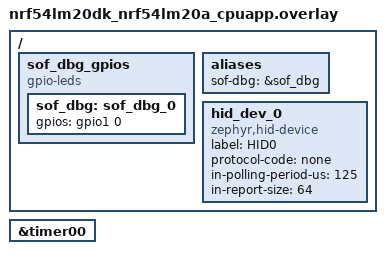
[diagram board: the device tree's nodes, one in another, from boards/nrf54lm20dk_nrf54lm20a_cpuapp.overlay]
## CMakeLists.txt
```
#
# Copyright (c) 2018 Nordic Semiconductor
#
# SPDX-License-Identifier: LicenseRef-Nordic-5-Clause
#
cmake_minimum_required(VERSION 3.20.0)

find_package(Zephyr REQUIRED HINTS $ENV{ZEPHYR_BASE})
project(NONE)

include(${ZEPHYR_BASE}/samples/subsys/usb/common/common.cmake)

FILE(GLOB app_sources src/*.c)
# NORDIC SDK APP START
target_sources(app PRIVATE ${app_sources})
# NORDIC SDK APP END

# if (CONFIG_CODE_DATA_RELOCATION)
# zephyr_code_relocate(FILES src/main.c LOCATION MYTCM NOKEEP)
# zephyr_code_relocate(FILES ../../../subsys/esb/esb.c LOCATION MYTCM NOKEEP)
# zephyr_code_relocate(FILES ../../../subsys/esb/esb_dppi.c LOCATION MYTCM NOKEEP)
# endif()
```

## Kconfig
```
#
# Copyright (c) 2020 Nordic Semiconductor
#
# SPDX-License-Identifier: LicenseRef-Nordic-5-Clause
#

source "Kconfig.zephyr"
source "samples/subsys/usb/common/Kconfig.sample_usbd"
```

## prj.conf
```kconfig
#
# Copyright (c) 2019 Nordic Semiconductor ASA
#
# SPDX-License-Identifier: LicenseRef-Nordic-5-Clause
#
CONFIG_NCS_SAMPLES_DEFAULTS=y

CONFIG_SPIN_VALIDATE=n
CONFIG_PM=n
CONFIG_TIMESLICING=n

CONFIG_DK_LIBRARY=y

CONFIG_USB_DEVICE_STACK_NEXT=y
CONFIG_UDC_DRIVER_LOG_LEVEL_WRN=y

CONFIG_USBD_HID_SUPPORT=y
CONFIG_USBD_LOG_LEVEL_WRN=y
CONFIG_USBD_HID_LOG_LEVEL_WRN=y

CONFIG_SAMPLE_USBD_MANUFACTURER="Nordic Semiconductor"
CONFIG_SAMPLE_USBD_PRODUCT="ESB dongle demo"
CONFIG_SAMPLE_USBD_SELF_POWERED=n
CONFIG_SAMPLE_USBD_MAX_POWER=50

CONFIG_NRFX_GPPI=y

CONFIG_NRFX_TIMER=y
CONFIG_LOG=y
```

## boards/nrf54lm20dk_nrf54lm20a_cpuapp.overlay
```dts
/*
 * Copyright (c) 2025 Nordic Semiconductor
 *
 * SPDX-License-Identifier: LicenseRef-Nordic-5-Clause
 */

/ {
	/* SOF debug GPIO: toggle on each timer IRQ (20us after SOF).
	 * Connect logic analyzer probe here to verify SOF->timer chain.
	 * Change <&gpio1 0 ...> to any free header pin as needed.
	 */
	sof_dbg_gpios {
		compatible = "gpio-leds";
		sof_dbg: sof_dbg_0 {
			gpios = <&gpio1 0 GPIO_ACTIVE_HIGH>;
		};
	};

	aliases {
		sof-dbg = &sof_dbg;
	};

	hid_dev_0: hid_dev_0 {
		compatible = "zephyr,hid-device";
		label = "HID0";
		protocol-code = "none";
		in-polling-period-us = <125>;
		in-report-size = <64>;
	};
};

&timer00 {
	status = "okay";
};
```

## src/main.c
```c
/*
 * Copyright (c) 2018 Nordic Semiconductor ASA
 *
 * SPDX-License-Identifier: LicenseRef-Nordic-5-Clause
 */
#include <string.h>
#include <zephyr/device.h>
#include <zephyr/devicetree.h>
#include <zephyr/usb/usbd.h>
#include <zephyr/logging/log.h>
#include <nrfx.h>
#include <zephyr/kernel.h>
#include <zephyr/types.h>
#include <zephyr/pm/device_runtime.h>
#include <dk_buttons_and_leds.h>
#include "app_usbd.h"

LOG_MODULE_REGISTER(usb_sof_dppi, LOG_LEVEL_INF);

static void usbd_in_report_done_cb(void)
{
	LOG_INF("USB device in report done callback");

}

int main(void)
{
	int err;

	LOG_INF("Enhanced ShockBurst prx sample");

	err = app_usbd_init(usbd_in_report_done_cb);
	if (err) {
		LOG_ERR("Failed to initialize USB device, err %d", err);
		return 0;
	}
	err = app_usbd_enable();
	if (err) {
		LOG_ERR("Failed to enable USB device, err %d", err);
		return 0;
	}

	/* return to idle thread */
	return 0;
}
```

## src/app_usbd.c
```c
/*
 * Copyright (c) 2025 Nordic Semiconductor
 *
 * SPDX-License-Identifier: LicenseRef-Nordic-5-Clause
 */

#include <zephyr/usb/usb_device.h>
#include <zephyr/usb/usbd.h>
#include <zephyr/usb/class/usbd_hid.h>
#include <sample_usbd.h>
#include "app_usbd.h"
#include <hal/nrf_gpiote.h>
#include <helpers/nrfx_gppi.h>
#include <nrfx_timer.h>
#include <zephyr/drivers/gpio.h>
#include <zephyr/logging/log.h>
LOG_MODULE_REGISTER(app_usbd, LOG_LEVEL_INF);

/** @brief Symbol specifying time in milliseconds to wait for handler execution. */
#define TIME_TO_WAIT_MS 5000UL
#define TIME_TO_WAIT_US 20UL
/* NRFX_TIMER */
/** @brief Symbol specifying timer instance to be used in nrfx_timer/timer example. */
#define TIMER_INST_IDX 00

/** @brief TIMER instance used in the example. */
static nrfx_timer_t timer_inst = NRFX_TIMER_INSTANCE(NRF_TIMER_INST_GET(TIMER_INST_IDX));

/* Debug GPIO: toggles each time the timer fires (20us after USB SOF). */
static const struct gpio_dt_spec sof_dbg_gpio = GPIO_DT_SPEC_GET(DT_ALIAS(sof_dbg), gpios);


static int get_report_cb(const struct device *dev,
			 const uint8_t type, const uint8_t id, const uint16_t len,
			 uint8_t *const buf);
static void input_report_done_cb(const struct device *dev, const uint8_t *const report);
static void output_report_cb(const struct device *dev,
			     const uint16_t len,
			     const uint8_t *const buf);


static const uint8_t hid_report_desc[] = HID_MOUSE_REPORT_DESC(2);

static app_usbd_in_report_done_cb usr_in_report_done_cb;


/**
 * @brief Function for handling TIMER driver events.
 *
 * @param[in] event_type Timer event.
 * @param[in] p_context  General purpose parameter set during initialization of
 *                       the timer. This parameter can be used to pass
 *                       additional information to the handler function, for
 *                       example, the timer ID.
 */
static void timer_handler(nrf_timer_event_t event_type, void * p_context)
{
    if(event_type == NRF_TIMER_EVENT_COMPARE0)
    {
        gpio_pin_toggle_dt(&sof_dbg_gpio);
        // char * p_msg = p_context;
        // LOG_INF("Timer finished. Context passed to the handler: >%s<", p_msg);
    }
}

static int set_report_cb(const struct device *dev,
			 const uint8_t type, const uint8_t id, const uint16_t len,
			 const uint8_t *const buf)
{
	if (type != HID_REPORT_TYPE_OUTPUT) {
		return -ENOTSUP;
	}

	return 0;
}

static void iface_ready_cb(const struct device *dev, const bool ready)
{
}

static uint32_t idle_duration;

static void set_idle_cb(const struct device *dev,
			const uint8_t id, const uint32_t duration)
{
	idle_duration = duration;
}

static uint32_t get_idle_cb(const struct device *dev, const uint8_t id)
{
	return idle_duration;
}

static uint32_t idle_duration;

static const struct hid_device_ops hid_ops = {
	.iface_ready = iface_ready_cb,
	.get_report = get_report_cb,
	.set_report = set_report_cb,
	.input_report_done = input_report_done_cb,
	.output_report = output_report_cb,
	.set_idle = set_idle_cb,
	.get_idle = get_idle_cb
};

static struct usbd_context *sample_usbd;

static const struct device *hid_device = DEVICE_DT_GET_ONE(zephyr_hid_device);


static void output_report_cb(const struct device *dev,
			     const uint16_t len,
			     const uint8_t *const buf)
{
}

static void msg_cb(struct usbd_context *const usbd_ctx,
		   const struct usbd_msg *const msg)
{
	if (usbd_can_detect_vbus(usbd_ctx)) {
		if (msg->type == USBD_MSG_VBUS_READY) {
			usbd_enable(usbd_ctx);
		} else if (msg->type == USBD_MSG_VBUS_REMOVED) {
			usbd_disable(usbd_ctx);
		}
	}
}

int app_usbd_init(app_usbd_in_report_done_cb cb)
{
	int err;

	err = hid_device_register(hid_device,
				  hid_report_desc,
				  sizeof(hid_report_desc),
				  &hid_ops);

	if (!err) {
		sample_usbd = sample_usbd_init_device(msg_cb);
		err = (sample_usbd) ? 0 : -ENODEV;
	}

	if (!err) {
		usr_in_report_done_cb = cb;
	}

	return err;
}

int timer_init(void)
{
    int status;
    (void)status;

#if defined(__ZEPHYR__)
    IRQ_CONNECT(NRFX_IRQ_NUMBER_GET(NRF_TIMER_INST_GET(TIMER_INST_IDX)), IRQ_PRIO_LOWEST,
                nrfx_timer_irq_handler, &timer_inst, 0);
#endif
    uint32_t base_frequency = NRF_TIMER_BASE_FREQUENCY_GET(timer_inst.p_reg);
    nrfx_timer_config_t config = NRFX_TIMER_DEFAULT_CONFIG(base_frequency);
    config.bit_width = NRF_TIMER_BIT_WIDTH_32;
    config.p_context = "Some context";
    status = nrfx_timer_init(&timer_inst, &config, timer_handler);
    NRFX_ASSERT(status == 0);
    nrfx_timer_clear(&timer_inst);

    /* Configure SOF debug GPIO as output, initially low. */
    gpio_pin_configure_dt(&sof_dbg_gpio, GPIO_OUTPUT_LOW);
    /* Creating variable desired_ticks to store the output of nrfx_timer_ms_to_ticks function */
    // uint32_t desired_ticks = nrfx_timer_ms_to_ticks(&timer_inst, TIME_TO_WAIT_MS);
    // LOG_INF("Time to wait: %lu ms", TIME_TO_WAIT_MS);	
	uint32_t desired_ticks = nrfx_timer_us_to_ticks(&timer_inst, TIME_TO_WAIT_US);
    LOG_INF("Time to wait: %lu us", TIME_TO_WAIT_US);	
    /*
     * Setting the timer channel NRF_TIMER_CC_CHANNEL0 in the extended compare mode to stop the timer and
     * trigger an interrupt if internal counter register is equal to desired_ticks.
     */
    nrfx_timer_extended_compare(&timer_inst, NRF_TIMER_CC_CHANNEL0, desired_ticks,
                                NRF_TIMER_SHORT_COMPARE0_CLEAR_MASK | NRF_TIMER_SHORT_COMPARE0_STOP_MASK, true);

    // nrfx_timer_enable(&timer_inst);	
    // LOG_INF("Timer status: %s", nrfx_timer_is_enabled(&timer_inst) ? "enabled" : "disabled");
	return 0;
}

int dppi_usb_sof_timer_gpiote_setup(void)
{
	uint32_t usbhs_start_task = (uint32_t)&NRF_USBHS->TASKS_START;
	uint32_t usbhs_domain_id = nrfx_gppi_domain_id_get(usbhs_start_task);

	/* --- Connection 1: USBHS SOF → Timer START --- */
	uint32_t timer_task_addr = nrf_timer_task_address_get(timer_inst.p_reg, NRF_TIMER_TASK_START);
	uint32_t timer_domain_id = nrfx_gppi_domain_id_get(timer_task_addr);

	int err;
	nrfx_gppi_handle_t gppi_handle_timer;

	err = nrfx_gppi_domain_conn_alloc(usbhs_domain_id, timer_domain_id, &gppi_handle_timer);
	if (err) {
		LOG_ERR("Timer conn alloc failed: %d", err);
	}

	/* Retrieve the allocated DPPI channel in the USBHS domain and configure PUBLISH_SOF. */
	uint32_t usbhs_dppi_ch = nrfx_gppi_domain_channel_get(gppi_handle_timer, usbhs_domain_id);
	NRF_USBHS->PUBLISH_SOF = (usbhs_dppi_ch << USBHS_PUBLISH_SOF_CHIDX_Pos) |
							 (USBHS_PUBLISH_SOF_EN_Enabled << USBHS_PUBLISH_SOF_EN_Pos);

	err = nrfx_gppi_ep_attach(timer_task_addr, gppi_handle_timer);
	if (err) {
		LOG_ERR("Timer ep attach failed: %d", err);
	}

	/* --- Connection 2: USBHS SOF → GPIOTE30 OUT (reuse the same source DPPI channel) --- */
	uint32_t gpiote_task_addr = nrf_gpiote_task_address_get(NRF_GPIOTE30, NRF_GPIOTE_TASK_OUT_0);
	uint32_t gpiote_domain_id = nrfx_gppi_domain_id_get(gpiote_task_addr);

	nrfx_gppi_handle_t gppi_handle_gpiote;

	/*
	 * Pass the already-allocated USBHS DPPI channel as p_resource so that
	 * nrfx_gppi_ext_conn_alloc reuses it instead of allocating a new one.
	 * Both PPIB bridges will then be driven by the same PUBLISH_SOF channel,
	 * triggering both tasks simultaneously on every SOF event.
	 */
	nrfx_gppi_resource_t usbhs_resource = {
		.domain_id = (uint16_t)usbhs_domain_id,
		.channel   = (uint8_t)usbhs_dppi_ch,
	};
	err = nrfx_gppi_ext_conn_alloc(usbhs_domain_id, gpiote_domain_id,
				       &gppi_handle_gpiote, &usbhs_resource);
	if (err) {
		LOG_ERR("GPIOTE conn alloc failed: %d", err);
	}

	nrf_gpiote_task_configure(NRF_GPIOTE30, 0, 3,
				  NRF_GPIOTE_POLARITY_TOGGLE,
				  NRF_GPIOTE_INITIAL_VALUE_LOW);

	err = nrfx_gppi_ep_attach(gpiote_task_addr, gppi_handle_gpiote);
	if (err) {
		LOG_ERR("GPIOTE ep attach failed: %d", err);
	}

	nrf_gpiote_task_enable(NRF_GPIOTE30, 0);

	nrfx_timer_enable(&timer_inst);
	nrfx_gppi_conn_enable(gppi_handle_timer);
	nrfx_gppi_conn_enable(gppi_handle_gpiote);

	return 0;
}
int app_usbd_enable(void)
{
	int err;

	if (!usbd_can_detect_vbus(sample_usbd)) {
		err = usbd_enable(sample_usbd);
	} else {
		err = 0;
	}
	err = timer_init();

	if(err<0)
	{
		LOG_ERR("Timer init failed: %d", err);
		return err;
	}

	if (!err) {
		dppi_usb_sof_timer_gpiote_setup();
	}

	return err;
}

int app_usbd_submit_report(const uint8_t *report, uint16_t size)
{
	int err;

	if (unlikely(!report)) {
		err = -EINVAL;
	} else if (size != APP_USBD_DATA_SIZE) {
		err = -ENOTSUP;
	} else {
		err = 0;
	}

	if (!err) {
		err = hid_device_submit_report(hid_device,
					       size,
					       report);
	}

	return err;
}

static int get_report_cb(const struct device *dev,
			 const uint8_t type, const uint8_t id, const uint16_t len,
			 uint8_t *const buf)
{
	return 0;
}

static void input_report_done_cb(const struct device *dev,
				 const uint8_t *const report)
{
	if (usr_in_report_done_cb) {
		usr_in_report_done_cb();
	}
}
```

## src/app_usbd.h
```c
/*
 * Copyright (c) 2025 Nordic Semiconductor
 *
 * SPDX-License-Identifier: LicenseRef-Nordic-5-Clause
 */

#ifndef __APP_USBD_H_
#define __APP_USBD_H_

#ifdef __cplusplus
extern "C" {
#endif


#define APP_USBD_BUTTONS_IDX		0
#define APP_USBD_DX_IDX			1
#define APP_USBD_DY_IDX			2
#define APP_USBD_DW_IDX			3
#define APP_USBD_DATA_SIZE		4


typedef void (*app_usbd_in_report_done_cb)(void);


int app_usbd_init(app_usbd_in_report_done_cb cb);

int app_usbd_enable(void);

int app_usbd_submit_report(const uint8_t *report, uint16_t size);


#ifdef __cplusplus
}
#endif

#endif /* __APP_USBD_H_ */
```
